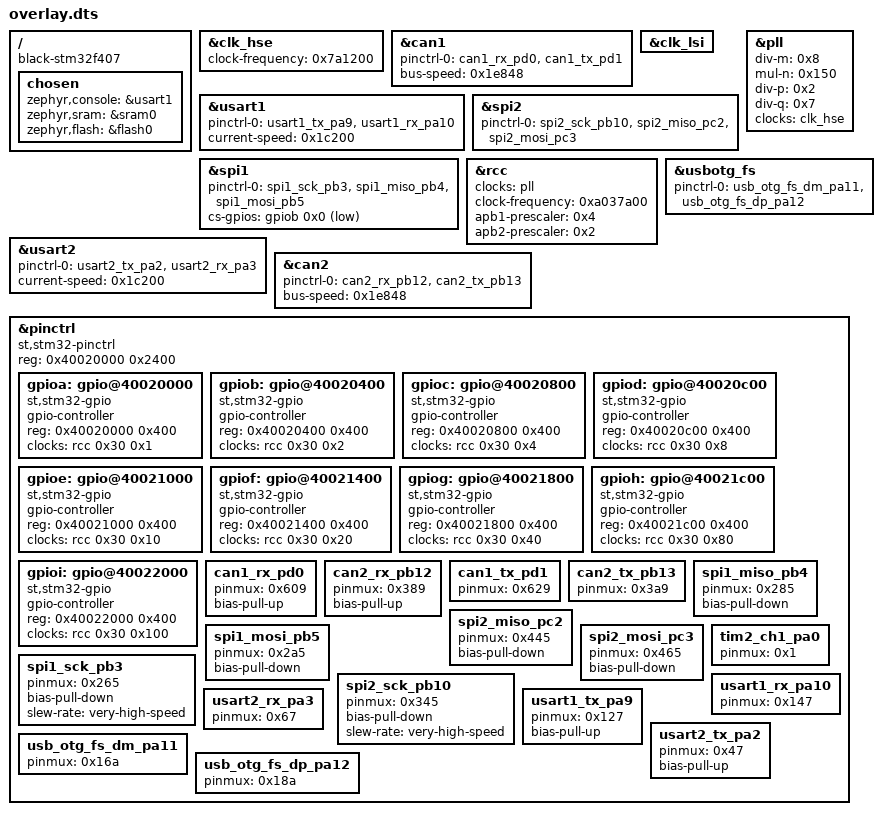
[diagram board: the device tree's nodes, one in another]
/ {
	compatible = "black-stm32f407";
	chosen {
		zephyr,console = &usart1;
		zephyr,sram = &sram0;
		zephyr,flash = &flash0;
	};
};
&clk_hse{
	status = "okay";
	clock-frequency = < 0x7a1200 >;
};
&can1{
	pinctrl-0 = < &can1_rx_pd0 &can1_tx_pd1 >;
	pinctrl-names = "default";
	bus-speed = < 0x1e848 >;
};
&usart1{
	status = "okay";
	pinctrl-0 = < &usart1_tx_pa9 &usart1_rx_pa10 >;
	pinctrl-names = "default";
	current-speed = < 0x1c200 >;
};
&clk_lsi{
	status = "okay";
};
&spi2{
	status = "okay";
	pinctrl-0 = < &spi2_sck_pb10 &spi2_miso_pc2 &spi2_mosi_pc3 >;
	pinctrl-names = "default";
};
&spi1{
	status = "okay";
	pinctrl-0 = < &spi1_sck_pb3 &spi1_miso_pb4 &spi1_mosi_pb5 >;
	pinctrl-names = "default";
	cs-gpios = < &gpiob 0x0 0x1 >;
};
&pll{
	status = "okay";
	div-m = < 0x8 >;
	mul-n = < 0x150 >;
	div-p = < 0x2 >;
	div-q = < 0x7 >;
	clocks = < &clk_hse >;
};
&rcc{
	clocks = < &pll >;
	clock-frequency = < 0xa037a00 >;
	apb1-prescaler = < 0x4 >;
	apb2-prescaler = < 0x2 >;
};
&usart2{
	status = "okay";
	pinctrl-0 = < &usart2_tx_pa2 &usart2_rx_pa3 >;
	pinctrl-names = "default";
	current-speed = < 0x1c200 >;
};
&can2{
	status = "okay";
	pinctrl-0 = < &can2_rx_pb12 &can2_tx_pb13 >;
	pinctrl-names = "default";
	bus-speed = < 0x1e848 >;
};
&usbotg_fs{
	status = "okay";
	pinctrl-0 = < &usb_otg_fs_dm_pa11 &usb_otg_fs_dp_pa12 >;
	pinctrl-names = "default";
};
&pinctrl{
	compatible = "st,stm32-pinctrl";
	#address-cells = < 0x1 >;
	#size-cells = < 0x1 >;
	reg = < 0x40020000 0x2400 >;
	gpioa: gpio@40020000 {
		compatible = "st,stm32-gpio";
		gpio-controller;
		#gpio-cells = < 0x2 >;
		reg = < 0x40020000 0x400 >;
		clocks = < &rcc 0x30 0x1 >;
	};
	gpiob: gpio@40020400 {
		compatible = "st,stm32-gpio";
		gpio-controller;
		#gpio-cells = < 0x2 >;
		reg = < 0x40020400 0x400 >;
		clocks = < &rcc 0x30 0x2 >;
	};
	gpioc: gpio@40020800 {
		compatible = "st,stm32-gpio";
		gpio-controller;
		#gpio-cells = < 0x2 >;
		reg = < 0x40020800 0x400 >;
		clocks = < &rcc 0x30 0x4 >;
	};
	gpiod: gpio@40020c00 {
		compatible = "st,stm32-gpio";
		gpio-controller;
		#gpio-cells = < 0x2 >;
		reg = < 0x40020c00 0x400 >;
		clocks = < &rcc 0x30 0x8 >;
	};
	gpioe: gpio@40021000 {
		compatible = "st,stm32-gpio";
		gpio-controller;
		#gpio-cells = < 0x2 >;
		reg = < 0x40021000 0x400 >;
		clocks = < &rcc 0x30 0x10 >;
	};
	gpiof: gpio@40021400 {
		compatible = "st,stm32-gpio";
		gpio-controller;
		#gpio-cells = < 0x2 >;
		reg = < 0x40021400 0x400 >;
		clocks = < &rcc 0x30 0x20 >;
	};
	gpiog: gpio@40021800 {
		compatible = "st,stm32-gpio";
		gpio-controller;
		#gpio-cells = < 0x2 >;
		reg = < 0x40021800 0x400 >;
		clocks = < &rcc 0x30 0x40 >;
	};
	gpioh: gpio@40021c00 {
		compatible = "st,stm32-gpio";
		gpio-controller;
		#gpio-cells = < 0x2 >;
		reg = < 0x40021c00 0x400 >;
		clocks = < &rcc 0x30 0x80 >;
	};
	gpioi: gpio@40022000 {
		compatible = "st,stm32-gpio";
		gpio-controller;
		#gpio-cells = < 0x2 >;
		reg = < 0x40022000 0x400 >;
		clocks = < &rcc 0x30 0x100 >;
	};
	can1_rx_pd0: can1_rx_pd0 {
		pinmux = < 0x609 >;
		bias-pull-up;
	};
	can2_rx_pb12: can2_rx_pb12 {
		pinmux = < 0x389 >;
		bias-pull-up;
	};
	can1_tx_pd1: can1_tx_pd1 {
		pinmux = < 0x629 >;
	};
	can2_tx_pb13: can2_tx_pb13 {
		pinmux = < 0x3a9 >;
	};
	spi1_miso_pb4: spi1_miso_pb4 {
		pinmux = < 0x285 >;
		bias-pull-down;
	};
	spi2_miso_pc2: spi2_miso_pc2 {
		pinmux = < 0x445 >;
		bias-pull-down;
	};
	spi1_mosi_pb5: spi1_mosi_pb5 {
		pinmux = < 0x2a5 >;
		bias-pull-down;
	};
	spi2_mosi_pc3: spi2_mosi_pc3 {
		pinmux = < 0x465 >;
		bias-pull-down;
	};
	spi1_sck_pb3: spi1_sck_pb3 {
		pinmux = < 0x265 >;
		bias-pull-down;
		slew-rate = "very-high-speed";
	};
	spi2_sck_pb10: spi2_sck_pb10 {
		pinmux = < 0x345 >;
		bias-pull-down;
		slew-rate = "very-high-speed";
	};
	tim2_ch1_pa0: tim2_ch1_pa0 {
		pinmux = < 0x1 >;
	};
	usart1_rx_pa10: usart1_rx_pa10 {
		pinmux = < 0x147 >;
	};
	usart2_rx_pa3: usart2_rx_pa3 {
		pinmux = < 0x67 >;
	};
	usart1_tx_pa9: usart1_tx_pa9 {
		pinmux = < 0x127 >;
		bias-pull-up;
	};
	usart2_tx_pa2: usart2_tx_pa2 {
		pinmux = < 0x47 >;
		bias-pull-up;
	};
	usb_otg_fs_dm_pa11: usb_otg_fs_dm_pa11 {
		pinmux = < 0x16a >;
	};
	usb_otg_fs_dp_pa12: usb_otg_fs_dp_pa12 {
		pinmux = < 0x18a >;
	};
};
